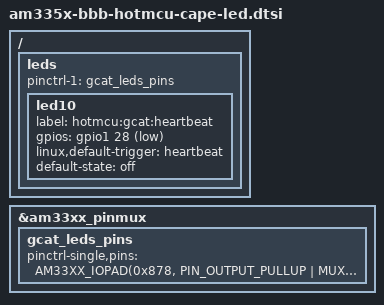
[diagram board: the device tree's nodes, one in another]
/*
with TI am335x BSP 06.03.00.106
with HAOYU / www.hotmcu.com cape
greatcat@ms18.hinet.net
20201231
If this document helps you and buy street cats a fish can.
*/
//

&am33xx_pinmux {
		gcat_leds_pins: gcat_leds_pins {
			pinctrl-single,pins = <
				//0x078 0x2f      /* KEY_RIGHT gpmc_ben1.gpio1_28, INPUT | PULLDIS | MODE7 */
				AM33XX_IOPAD(0x878, PIN_OUTPUT_PULLUP | MUX_MODE7) //(U18) gpmc_be1n.gpio1[28] 

			>;
		};
};

/{
	leds {
		pinctrl-1 = <&gcat_leds_pins>;

		led10 {
			label = "hotmcu:gcat:heartbeat";
			gpios = <&gpio1 28 GPIO_ACTIVE_LOW>;
			linux,default-trigger = "heartbeat";
			default-state = "off";
		};
	};

};
